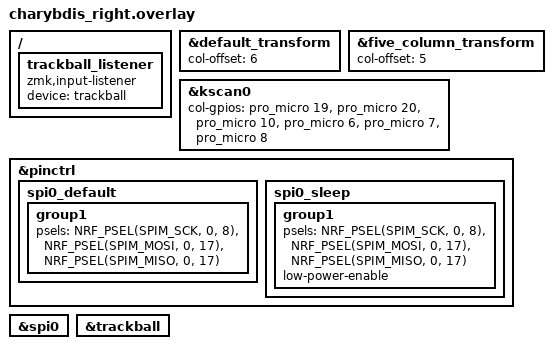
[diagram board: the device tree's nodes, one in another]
/*
 * Copyright (c) 2020 ZMK Contributors
 *
 * SPDX-License-Identifier: MIT
 */
 
#include "charybdis.dtsi"
#include "charybdis_3610.dtsi"

&default_transform {
	col-offset = <6>;
};

&five_column_transform {
	col-offset = <5>;
};

&kscan0 {
	col-gpios
		= <&pro_micro 19 (GPIO_ACTIVE_HIGH | GPIO_PULL_DOWN)>
		, <&pro_micro 20 (GPIO_ACTIVE_HIGH | GPIO_PULL_DOWN)>
		, <&pro_micro 10 (GPIO_ACTIVE_HIGH | GPIO_PULL_DOWN)>
		, <&pro_micro 6 (GPIO_ACTIVE_HIGH | GPIO_PULL_DOWN)>
		, <&pro_micro 7 (GPIO_ACTIVE_HIGH | GPIO_PULL_DOWN)>
		, <&pro_micro 8 (GPIO_ACTIVE_HIGH | GPIO_PULL_DOWN)>
		;
};

&pinctrl {
    spi0_default: spi0_default {
        group1 {
            psels = <NRF_PSEL(SPIM_SCK, 0, 8)>,
                <NRF_PSEL(SPIM_MOSI, 0, 17)>,
                <NRF_PSEL(SPIM_MISO, 0, 17)>;
        };
    };

    spi0_sleep: spi0_sleep {
        group1 {
            psels = <NRF_PSEL(SPIM_SCK, 0, 8)>,
                <NRF_PSEL(SPIM_MOSI, 0, 17)>,
                <NRF_PSEL(SPIM_MISO, 0, 17)>;
            low-power-enable;
        };
    };
};

&spi0 {
    status = "okay";
};

&trackball {
    status = "okay";
};

/ {
  trackball_listener {
    compatible = "zmk,input-listener";
    device = <&trackball>;

  };
};
